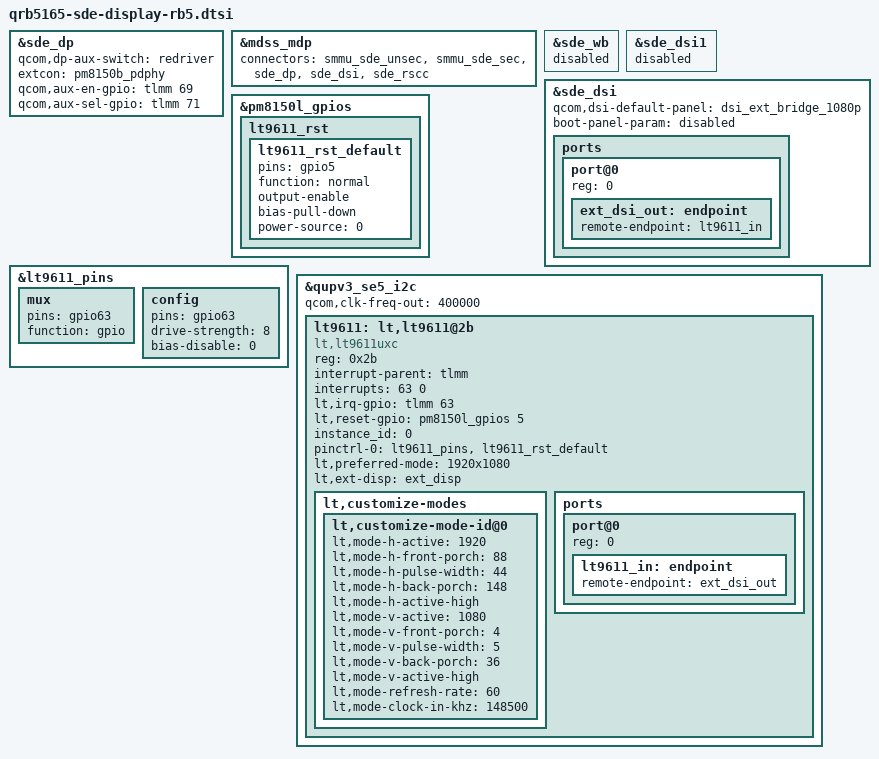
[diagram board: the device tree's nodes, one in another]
#include "kona-sde-display.dtsi"

&sde_dp {
	qcom,dp-aux-switch = <&redriver>;
	extcon = <&pm8150b_pdphy>;
	qcom,aux-en-gpio = <&tlmm 69 0>;
	qcom,aux-sel-gpio = <&tlmm 71 0>;
};

&mdss_mdp {
	connectors = <&smmu_sde_unsec &smmu_sde_sec
			&sde_dp &sde_dsi &sde_rscc>;
};

&sde_wb {
	status = "disabled";
};

&sde_dsi1 {
	status = "disabled";
};

&sde_dsi {
	qcom,dsi-default-panel = <&dsi_ext_bridge_1080p>;
	boot-panel-param = "disabled";

	ports {
		#address-cells = <1>;
		#size-cells = <0>;

		port@0 {
			reg = <0>;
			ext_dsi_out: endpoint {
				remote-endpoint = <&lt9611_in>;
			};
		};
	};
};

&pm8150l_gpios {
	lt9611_rst {
		lt9611_rst_default: lt9611_rst_default {
			    pins = "gpio5";
			    function = "normal";
			    output-enable;
			    bias-pull-down;
			    power-source = <0>;
		};
	};
};

&lt9611_pins {
	mux {
		pins = "gpio63";
		function = "gpio";
	};

	config {
		pins = "gpio63";
		drive-strength = <8>;
		bias-disable = <0>;
	};
};

&qupv3_se5_i2c {
	status = "okay";
	qcom,clk-freq-out = <400000>;

	lt9611: lt,lt9611@2b {
		compatible = "lt,lt9611uxc";
		reg = <0x2b>;
		interrupt-parent = <&tlmm>;
		interrupts = <63 0>;
		interrupt-names = "lt_irq";
		lt,irq-gpio = <&tlmm 63 0x0>;
		lt,reset-gpio = <&pm8150l_gpios 5 0>;
		instance_id = <0>;

		pinctrl-names = "default";
		pinctrl-0 = <&lt9611_pins &lt9611_rst_default>;

		lt,preferred-mode = "1920x1080";

		lt,ext-disp = <&ext_disp>;

		lt,customize-modes {
			lt,customize-mode-id@0 {
				lt,mode-h-active = <1920>;
				lt,mode-h-front-porch = <88>;
				lt,mode-h-pulse-width = <44>;
				lt,mode-h-back-porch = <148>;
				lt,mode-h-active-high;
				lt,mode-v-active = <1080>;
				lt,mode-v-front-porch = <4>;
				lt,mode-v-pulse-width = <5>;
				lt,mode-v-back-porch = <36>;
				lt,mode-v-active-high;
				lt,mode-refresh-rate = <60>;
				lt,mode-clock-in-khz = <148500>;
			};
		};

		ports {
			#address-cells = <1>;
			#size-cells = <0>;
			port@0 {
				reg = <0>;
				lt9611_in: endpoint {
					remote-endpoint = <&ext_dsi_out>;
				};
			};
		};
	};
};

